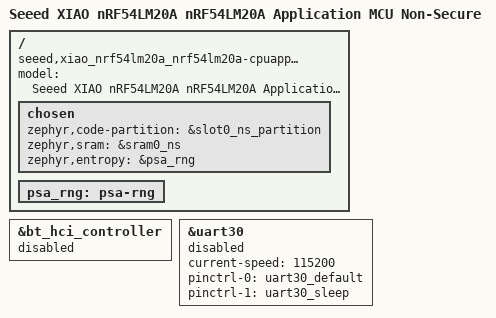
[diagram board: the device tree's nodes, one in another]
/*
 * Copyright The Zephyr Project Contributors
 *
 * SPDX-License-Identifier: Apache-2.0
 */

/dts-v1/;

#define USE_NON_SECURE_ADDRESS_MAP 1

#include "nrf54lm20a_cpuapp_common.dtsi"
#include "seeed_xiao_connector.dtsi"

/ {
	compatible = "seeed,xiao_nrf54lm20a_nrf54lm20a-cpuapp-ns";
	model = "Seeed XIAO nRF54LM20A nRF54LM20A Application MCU Non-Secure";

	chosen {
		zephyr,code-partition = &slot0_ns_partition;
		zephyr,sram = &sram0_ns;
		zephyr,entropy = &psa_rng;
	};

	/delete-node/ rng;

	psa_rng: psa-rng {
		status = "okay";
	};
};

&bt_hci_controller {
	status = "disabled";
};

&uart30 {
	/* Disable so that TF-M can use this UART */
	status = "disabled";

	current-speed = <115200>;
	pinctrl-0 = <&uart30_default>;
	pinctrl-1 = <&uart30_sleep>;
	pinctrl-names = "default", "sleep";
};

/* Include default memory partition configuration file */
#include <vendor/nordic/nrf54lm20a_cpuapp_ns_partition.dtsi>
